# ZB32L030 register map
Vendor: ZBit.; Series: ZB32L03X; File version: 1.0
CPU: CM0+ r1p0, little endian, no MPU, no FPU, VTOR, 2 interrupt priority bits
Registers are 32-bit, read-write, reset 0x0 unless marked. A register's access mark holds for its fields unless they carry their own. Offsets are from the block's base; [hi:lo] are bit positions; {n}, {i} and the like mark numbered series.

## TIM — Advance Timer
Base 0x40001000
Same registers: TIM1 0x40001000, TIM1A 0x40001200, TIM1B 0x40001300, TIM2 0x40003C00, TIM2A 0x40003D00, TIM2B 0x40003E00, TIM2C 0x40003F00
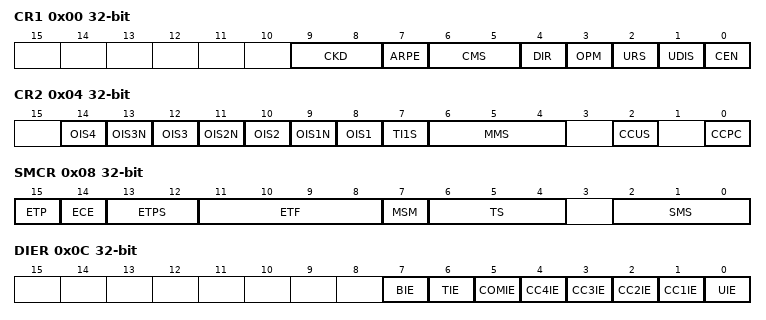
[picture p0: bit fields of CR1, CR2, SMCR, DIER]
0x00 CR1 — TIM Control Register1
  [9:8] CKD — Clock division
  [7] ARPE — Auto-reload preload enable
  [6:5] CMS — Center-aligned mode
  [4] DIR — Direction
  [3] OPM — One Pulse Mode
  [2] URS — Update Request Source
  [1] UDIS — Update Disable
  [0] CEN — Enable
0x04 CR2 — TIM Control Register 2
  [2n+6] OIS{n} (n=1..4)
  [13] OIS3N
  [11] OIS2N
  [9] OIS1N
  [7] TI1S
  [6:4] MMS
    0=RESET; 1=ENABLE; 2=UPDATE; 3=CMP_PLUSE (Compare Pulse); {v}=OC{v-3}REF (OC{v-3}REF signal is used as trigger output) (v=4..7)
  [2] CCUS — Capture/compare control update selection
  [0] CCPC
0x08 SMCR — TIM Master mode Control Register
  [15] ETP
  [14] ECE
  [13:12] ETPS
    0=ETRP_DIV1 (ETRP frequency divided by 1); 1=ETRP_DIV2 (ETRP frequency divided by 2); 2=ETRP_DIV4 (ETRP frequency divided by 4); 3=ETRP_DIV8 (ETRP frequency divided by 8)
  [11:8] ETF — External trigger filter
  [7] MSM
  [6:4] TS — Trigger selection
    {v}=ITR{v} (Internal Trigger {v}) (v=0..3); 4=TI1F_ED (TI1 Edge Detector); 5=TI1FP1 (Filtered Timer Input 1); 6=TI1FP2 (Filtered Timer Input 2); 7=ETRF (External Trigger input)
  [2:0] SMS — Slave mode selection
    0=SLAVE_OFF (Slave mode disabled); 1=ENCODER_MODE_1; 2=ENCODER_MODE_2; 3=ENCODER_MODE_3; 4=RESET_MODE; 5=GATED_MODE; 6=TRIGGER_MODE; 7=EXT_CLK_MODE_1 (External Clock mode 1)
0x0C DIER — TIM Interrupt Enable Register
  [7] BIE — Break interrupt enable (Advance Timer)
  [6] TIE
  [5] COMIE
  [n] CC{n}IE (n=1..4)
  [0] UIE
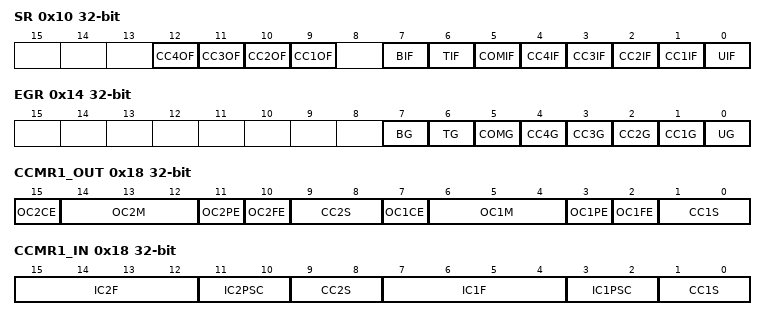
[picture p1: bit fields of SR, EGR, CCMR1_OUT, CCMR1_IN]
0x10 SR — TIM Status Register
  [n+8] CC{n}OF (n=1..4), [7] BIF, [6] TIF, [5] COMIF, [n] CC{n}IF (n=1..4), [0] UIF
0x14 EGR — TIM Event Trig Register
  [7] BG wo — Break generation
  [6] TG wo — Trigger generation
  [5] COMG wo — Capture/Compare control update generation
  [n] CC{n}G wo (n=1..4) — Capture/Compare {n} generation
  [0] UG wo — Update generation
0x18 CCMR1_OUT — TIM Capture/Compare Mode Register 1 (Output mode)
  [15] OC2CE — Output Compare 2 clear enable
  [14:12] OC2M — Output Compare 2 mode
  [11] OC2PE — Output Compare 2 preload enable
  [10] OC2FE — Output Compare 2 fast enable
  [9:8] CC2S — Capture/Compare 2 selection
  [7] OC1CE — Output Compare 1 clear enable
  [6:4] OC1M — Output Compare 1 mode
    0=FROZEN; 1=CH1_ACTIVE (Set channel 1 to active level on match); 2=CH1_INACTIVE (Set channel 1 to inactive level on match.); 3=TOGGLE; 4=FORCE_INACTIVE (Force inactive level); 5=FORCE_ACTIVE (Force active level); 6=PWM_MODE1; 7=PWM_MODE2
  [3] OC1PE — Output Compare 1 preload enable
  [2] OC1FE — Output Compare 1 fast enable
  [1:0] CC1S — Capture/Compare 1 selection
0x18 CCMR1_IN — TIM Capture/Compare Mode Register 1 (Input mode)
  [15:12] IC2F — Input capture 2 filter
  [11:10] IC2PSC — Input capture 2 prescaler
  [9:8] CC2S — Capture/Compare 2 selection
  [7:4] IC1F — Input capture 1 filter
  [3:2] IC1PSC — Input capture 1 prescaler
  [1:0] CC1S — Capture/Compare 1 Selection
    0=OUTPUT (CC1 channel is configured as output); 1=INPUT_TI1 (CC1 channel is configured as input, IC1 is mapped on TI1); 2=INPUT_TI2 (CC1 channel is configured as input, IC1 is mapped on TI2); 3=INPUT_TRC (CC1 channel is configured as input, IC1 is mapped on TRC)
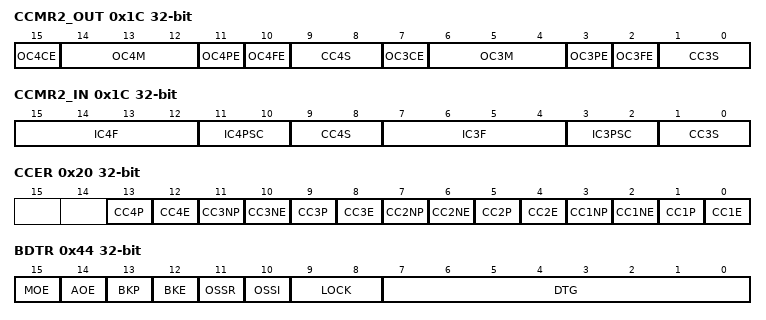
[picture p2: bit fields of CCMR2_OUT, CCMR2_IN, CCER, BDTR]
0x1C CCMR2_OUT — TIM Capture/Compare Mode Register 2 (Output mode)
  [15] OC4CE — Output Compare 4 clear enable
  [14:12] OC4M — Output Compare 4 mode
  [11] OC4PE — Output Compare 4 preload enable
  [10] OC4FE — Output Compare 4 fast enable
  [9:8] CC4S — Capture/Compare 4 selection
  [7] OC3CE — Output Compare 3 clear enable
  [6:4] OC3M — Output Compare 3 mode
  [3] OC3PE — Output Compare 3 preload enable
  [2] OC3FE — Output Compare 3 fast enable
  [1:0] CC3S — Capture/Compare 3 selection
0x1C CCMR2_IN — TIM Capture/Compare Mode Register 2 (Input mode)
  [15:12] IC4F — Input capture 4 filter
  [11:10] IC4PSC — Input capture 4 prescaler
  [9:8] CC4S — Capture/Compare 4 selection
  [7:4] IC3F — Input capture 3 filter
  [3:2] IC3PSC — Input capture 3 prescaler
  [1:0] CC3S — Capture/Compare 3 Selection
0x20 CCER — TIM Captuer/Compare Enable Register
  [4n-3] CC{n}P (n=1..4) — Capture/Compare {n} output polarity
  [4n-4] CC{n}E (n=1..4) — Capture/Compare {n} output enable
  [11] CC3NP — Capture/Compare 3 output polarity
  [10] CC3NE — Capture/Compare 3 output polarity
  [7] CC2NP — Capture/Compare 2 output polarity
  [6] CC2NE — Capture/Compare 2 output polarity
  [3] CC1NP — Capture/Compare 1 output polarity
  [2] CC1NE — Capture/Compare 1 output polarity
0x24 CNT — TIM Count
  [15:0] CNT — Counter value
0x28 PSC — TIM Prescale Register
  [15:0] PSC — Prescaler value
0x2C ARR — TIM Auto Load Register
  [15:0] ARR
0x30 RCR — TIM Repeate Count Register
  [7:0] REP — Repetition counter value
0x34 CCR1 reset 0xFFF — Captuer/Compare Register1
  [15:0] CCR1 — Capture/Compare 1 value
0x38 CCR2 — Capture/Compare Register2
  [15:0] CCR2 — Capture/Compare 2 value
0x3C CCR3 — Capture/Compare Register3
  [15:0] CCR3 — Capture/Compare 3 value
0x40 CCR4 — TIM Capture/Compare Register4
  [15:0] CCR4 — Capture/Compare 4 value
0x44 BDTR — TIM Brush and DEAD Register
  [15] MOE — Main output enable
  [14] AOE — Automatic output enable
  [13] BKP — Break polarity
  [12] BKE — Break enable
  [11] OSSR — Off-state selection for Run mode
  [10] OSSI — Off-state selection for Idle mode
  [9:8] LOCK — Lock Configuration
    0=OFF (Lock off); 1=LV1 (Lock level 1); 2=LV2 (Lock level 2); 3=LV3 (Lock level 3)
  [7:0] DTG — Dead-time generator setup
